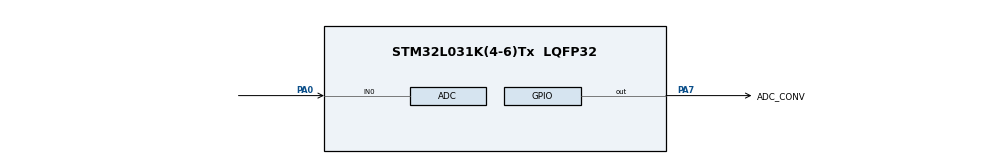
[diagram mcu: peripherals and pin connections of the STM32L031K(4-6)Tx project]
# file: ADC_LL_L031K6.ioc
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ADC.ClockPrescaler=ADC_CLOCK_SYNC_PCLK_DIV4
ADC.LowPowerFrequencyMode=ENABLE
ADC.OversamplingMode=ENABLE
ADC.Ratio=ADC_OVERSAMPLING_RATIO_16
ADC.RightBitShift=ADC_RIGHTBITSHIFT_4
ADC.SamplingTime=ADC_SAMPLETIME_160CYCLES_5
Mcu.Family=STM32L0
Mcu.Name=STM32L031K(4-6)Tx
Mcu.Package=LQFP32
PA0-CK_IN.Mode=IN0
PA0-CK_IN.Signal=ADC_IN0
PA13.GPIO_Label=TMS
PA13.Mode=Serial_Wire
PA13.Signal=SYS_SWDIO
PA14.GPIO_Label=TCK
PA14.Mode=Serial_Wire
PA14.Signal=SYS_SWCLK
PA7.GPIO_Label=ADC_CONV
PA7.GPIO_Speed=GPIO_SPEED_FREQ_VERY_HIGH
PA7.Signal=GPIO_Output
PC14-OSC32_IN.Mode=LSE-External-Oscillator
PC14-OSC32_IN.Signal=RCC_OSC32_IN
PC15-OSC32_OUT.Mode=LSE-External-Oscillator
PC15-OSC32_OUT.Signal=RCC_OSC32_OUT
ProjectManager.HeapSize=0x200
ProjectManager.StackSize=0x400
ProjectManager.TargetToolchain=STM32CubeIDE
RCC.AHBFreq_Value=32000000
RCC.APB1Freq_Value=32000000
RCC.APB1TimFreq_Value=32000000
RCC.APB2Freq_Value=32000000
RCC.APB2TimFreq_Value=32000000
RCC.HCLKFreq_Value=32000000
RCC.HSE_VALUE=8000000
RCC.HSI16_VALUE=16000000
RCC.HSI48_VALUE=48000000
RCC.HSI_VALUE=16000000
RCC.MSI_VALUE=2097000
RCC.PLLMUL=RCC_PLLMUL_4
RCC.SYSCLKFreq_VALUE=32000000
RCC.SYSCLKSource=RCC_SYSCLKSOURCE_PLLCLK
RCC.VCOOutputFreq_Value=64000000
VP_ADC_Vref_Input.Mode=IN-Vrefint
board=NUCLEO-L031K6

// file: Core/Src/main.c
/* USER CODE BEGIN Header */
/**
  ******************************************************************************
  * @file           : main.c
  * @brief          : Main program body
  ******************************************************************************
  * @attention
  *
  * Copyright (c) 2024 STMicroelectronics.
  * All rights reserved.
  *
  * This software is licensed under terms that can be found in the LICENSE file
  * in the root directory of this software component.
  * If no LICENSE file comes with this software, it is provided AS-IS.
  *
  ******************************************************************************
  */
/* USER CODE END Header */
#include "main.h"

/* USER CODE BEGIN PD */
#define VREFINT_CAL_ADDR                0x1FF80078  /* datasheet p. 19 */
#define VREFINT_CAL ((uint16_t*) VREFINT_CAL_ADDR)
#define VDDA_CHARAC						3.0
/* USER CODE END PD */

/* USER CODE BEGIN PV */
uint16_t adc_res1, adc_res2;
float adc_res1_V, adc_res2_V;
/* USER CODE END PV */

void SystemClock_Config(void);
static void MX_GPIO_Init(void);
static void MX_ADC_Init(void);

int main(void)
{

  /* MCU Configuration--------------------------------------------------------*/

  /* Reset of all peripherals, Initializes the Flash interface and the Systick. */
  LL_APB2_GRP1_EnableClock(LL_APB2_GRP1_PERIPH_SYSCFG);
  LL_APB1_GRP1_EnableClock(LL_APB1_GRP1_PERIPH_PWR);

  /* Configure the system clock */
  SystemClock_Config();

  /* Initialize all configured peripherals */
  MX_GPIO_Init();
  MX_ADC_Init();
  /* USER CODE BEGIN 2 */

  LL_ADC_StartCalibration(ADC1);
  while (LL_ADC_IsCalibrationOnGoing(ADC1));  // Wait until calibration is complete

  LL_ADC_Enable(ADC1);
  while (!LL_ADC_IsEnabled(ADC1)); // Wait until ADC is ready

  /* USER CODE END 2 */

  /* Infinite loop */
  /* USER CODE BEGIN WHILE */
  while (1)
  {
	  LL_GPIO_SetOutputPin(ADC_CONV_GPIO_Port, ADC_CONV_Pin);
	// Start ADC conversion
	LL_ADC_REG_StartConversion(ADC1);

	// Poll for conversion completion
	while (!LL_ADC_IsActiveFlag_EOC(ADC1));  // Wait for conversion to complete
	adc_res1 = LL_ADC_REG_ReadConversionData12(ADC1);

	 LL_GPIO_ResetOutputPin(ADC_CONV_GPIO_Port, ADC_CONV_Pin);
	 LL_ADC_ClearFlag_EOC(ADC1);

	// Start another ADC conversion
	 LL_GPIO_SetOutputPin(ADC_CONV_GPIO_Port, ADC_CONV_Pin);
	LL_ADC_REG_StartConversion(ADC1);

	// Poll for conversion completion
	while (!LL_ADC_IsActiveFlag_EOC(ADC1));  // Wait for conversion to complete
	adc_res2 = LL_ADC_REG_ReadConversionData12(ADC1);
	LL_GPIO_ResetOutputPin(ADC_CONV_GPIO_Port, ADC_CONV_Pin);

	// Clear EOC (End of Conversion) flag
	LL_ADC_ClearFlag_EOC(ADC1);

	// Calculate voltage values based on ADC readings
	adc_res2_V = VDDA_CHARAC * (*VREFINT_CAL) / adc_res2;
	adc_res1_V = (adc_res2_V / 4095.0) * adc_res1;

	// Add delay
	LL_mDelay(500);
    /* USER CODE END WHILE */

  }
}

void SystemClock_Config(void)
{
  LL_FLASH_SetLatency(LL_FLASH_LATENCY_1);
  while(LL_FLASH_GetLatency()!= LL_FLASH_LATENCY_1)
  {
  }
  LL_PWR_SetRegulVoltageScaling(LL_PWR_REGU_VOLTAGE_SCALE1);
  while (LL_PWR_IsActiveFlag_VOS() != 0)
  {
  }
  LL_RCC_HSI_Enable();

   /* Wait till HSI is ready */
  while(LL_RCC_HSI_IsReady() != 1)
  {

  }
  LL_RCC_HSI_SetCalibTrimming(16);
  LL_RCC_PLL_ConfigDomain_SYS(LL_RCC_PLLSOURCE_HSI, LL_RCC_PLL_MUL_4, LL_RCC_PLL_DIV_2);
  LL_RCC_PLL_Enable();

   /* Wait till PLL is ready */
  while(LL_RCC_PLL_IsReady() != 1)
  {

  }
  LL_RCC_SetAHBPrescaler(LL_RCC_SYSCLK_DIV_1);
  LL_RCC_SetAPB1Prescaler(LL_RCC_APB1_DIV_1);
  LL_RCC_SetAPB2Prescaler(LL_RCC_APB2_DIV_1);
  LL_RCC_SetSysClkSource(LL_RCC_SYS_CLKSOURCE_PLL);

   /* Wait till System clock is ready */
  while(LL_RCC_GetSysClkSource() != LL_RCC_SYS_CLKSOURCE_STATUS_PLL)
  {

  }

  LL_Init1msTick(32000000);

  LL_SetSystemCoreClock(32000000);
}

static void MX_ADC_Init(void)
{

  LL_ADC_REG_InitTypeDef ADC_REG_InitStruct = {0};
  LL_ADC_InitTypeDef ADC_InitStruct = {0};

  LL_GPIO_InitTypeDef GPIO_InitStruct = {0};

  /* Peripheral clock enable */
  LL_APB2_GRP1_EnableClock(LL_APB2_GRP1_PERIPH_ADC1);

  LL_IOP_GRP1_EnableClock(LL_IOP_GRP1_PERIPH_GPIOA);
  /**ADC GPIO Configuration
  PA0-CK_IN   ------> ADC_IN0
  */
  GPIO_InitStruct.Pin = LL_GPIO_PIN_0;
  GPIO_InitStruct.Mode = LL_GPIO_MODE_ANALOG;
  GPIO_InitStruct.Pull = LL_GPIO_PULL_NO;
  LL_GPIO_Init(GPIOA, &GPIO_InitStruct);

  /** Configure Regular Channel
  */
  LL_ADC_REG_SetSequencerChAdd(ADC1, LL_ADC_CHANNEL_0);

  /** Configure Regular Channel
  */
  LL_ADC_REG_SetSequencerChAdd(ADC1, LL_ADC_CHANNEL_VREFINT);
  LL_ADC_SetCommonPathInternalCh(__LL_ADC_COMMON_INSTANCE(ADC1), LL_ADC_PATH_INTERNAL_VREFINT);

  /** Common config
  */
  ADC_REG_InitStruct.TriggerSource = LL_ADC_REG_TRIG_SOFTWARE;
  ADC_REG_InitStruct.SequencerDiscont = LL_ADC_REG_SEQ_DISCONT_DISABLE;
  ADC_REG_InitStruct.ContinuousMode = LL_ADC_REG_CONV_SINGLE;
  ADC_REG_InitStruct.DMATransfer = LL_ADC_REG_DMA_TRANSFER_NONE;
  ADC_REG_InitStruct.Overrun = LL_ADC_REG_OVR_DATA_PRESERVED;
  LL_ADC_REG_Init(ADC1, &ADC_REG_InitStruct);
  LL_ADC_SetSamplingTimeCommonChannels(ADC1, LL_ADC_SAMPLINGTIME_160CYCLES_5);
  LL_ADC_SetOverSamplingScope(ADC1, LL_ADC_OVS_GRP_REGULAR_CONTINUED);
  LL_ADC_ConfigOverSamplingRatioShift(ADC1, LL_ADC_OVS_RATIO_16, LL_ADC_OVS_SHIFT_RIGHT_4);
  LL_ADC_SetOverSamplingDiscont(ADC1, LL_ADC_OVS_REG_CONT);
  LL_ADC_REG_SetSequencerScanDirection(ADC1, LL_ADC_REG_SEQ_SCAN_DIR_FORWARD);
  LL_ADC_SetCommonFrequencyMode(__LL_ADC_COMMON_INSTANCE(ADC1), LL_ADC_CLOCK_FREQ_MODE_LOW);
  LL_ADC_DisableIT_EOC(ADC1);
  LL_ADC_DisableIT_EOS(ADC1);
  ADC_InitStruct.Clock = LL_ADC_CLOCK_SYNC_PCLK_DIV4;
  ADC_InitStruct.Resolution = LL_ADC_RESOLUTION_12B;
  ADC_InitStruct.DataAlignment = LL_ADC_DATA_ALIGN_RIGHT;
  ADC_InitStruct.LowPowerMode = LL_ADC_LP_MODE_NONE;
  LL_ADC_Init(ADC1, &ADC_InitStruct);

  /* Enable ADC internal voltage regulator */
  LL_ADC_EnableInternalRegulator(ADC1);
  /* Delay for ADC internal voltage regulator stabilization. */
  /* Compute number of CPU cycles to wait for, from delay in us. */
  /* Note: Variable divided by 2 to compensate partially */
  /* CPU processing cycles (depends on compilation optimization). */
  /* Note: If system core clock frequency is below 200kHz, wait time */
  /* is only a few CPU processing cycles. */
  uint32_t wait_loop_index;
  wait_loop_index = ((LL_ADC_DELAY_INTERNAL_REGUL_STAB_US * (SystemCoreClock / (100000 * 2))) / 10);
  while(wait_loop_index != 0)
  {
    wait_loop_index--;
  }

}

static void MX_GPIO_Init(void)
{
  LL_GPIO_InitTypeDef GPIO_InitStruct = {0};

  /* GPIO Ports Clock Enable */
  LL_IOP_GRP1_EnableClock(LL_IOP_GRP1_PERIPH_GPIOC);
  LL_IOP_GRP1_EnableClock(LL_IOP_GRP1_PERIPH_GPIOA);
  LL_IOP_GRP1_EnableClock(LL_IOP_GRP1_PERIPH_GPIOB);

  /**/
  LL_GPIO_ResetOutputPin(ADC_CONV_GPIO_Port, ADC_CONV_Pin);

  /**/
  GPIO_InitStruct.Pin = LL_GPIO_PIN_1;
  GPIO_InitStruct.Mode = LL_GPIO_MODE_ANALOG;
  GPIO_InitStruct.Pull = LL_GPIO_PULL_NO;
  LL_GPIO_Init(GPIOA, &GPIO_InitStruct);

  /**/
  GPIO_InitStruct.Pin = LL_GPIO_PIN_2;
  GPIO_InitStruct.Mode = LL_GPIO_MODE_ANALOG;
  GPIO_InitStruct.Pull = LL_GPIO_PULL_NO;
  LL_GPIO_Init(GPIOA, &GPIO_InitStruct);

  /**/
  GPIO_InitStruct.Pin = LL_GPIO_PIN_3;
  GPIO_InitStruct.Mode = LL_GPIO_MODE_ANALOG;
  GPIO_InitStruct.Pull = LL_GPIO_PULL_NO;
  LL_GPIO_Init(GPIOA, &GPIO_InitStruct);

  /**/
  GPIO_InitStruct.Pin = LL_GPIO_PIN_4;
  GPIO_InitStruct.Mode = LL_GPIO_MODE_ANALOG;
  GPIO_InitStruct.Pull = LL_GPIO_PULL_NO;
  LL_GPIO_Init(GPIOA, &GPIO_InitStruct);

  /**/
  GPIO_InitStruct.Pin = LL_GPIO_PIN_5;
  GPIO_InitStruct.Mode = LL_GPIO_MODE_ANALOG;
  GPIO_InitStruct.Pull = LL_GPIO_PULL_NO;
  LL_GPIO_Init(GPIOA, &GPIO_InitStruct);

  /**/
  GPIO_InitStruct.Pin = LL_GPIO_PIN_6;
  GPIO_InitStruct.Mode = LL_GPIO_MODE_ANALOG;
  GPIO_InitStruct.Pull = LL_GPIO_PULL_NO;
  LL_GPIO_Init(GPIOA, &GPIO_InitStruct);

  /**/
  GPIO_InitStruct.Pin = ADC_CONV_Pin;
  GPIO_InitStruct.Mode = LL_GPIO_MODE_OUTPUT;
  GPIO_InitStruct.Speed = LL_GPIO_SPEED_FREQ_VERY_HIGH;
  GPIO_InitStruct.OutputType = LL_GPIO_OUTPUT_PUSHPULL;
  GPIO_InitStruct.Pull = LL_GPIO_PULL_NO;
  LL_GPIO_Init(ADC_CONV_GPIO_Port, &GPIO_InitStruct);

  /**/
  GPIO_InitStruct.Pin = LL_GPIO_PIN_0;
  GPIO_InitStruct.Mode = LL_GPIO_MODE_ANALOG;
  GPIO_InitStruct.Pull = LL_GPIO_PULL_NO;
  LL_GPIO_Init(GPIOB, &GPIO_InitStruct);

  /**/
  GPIO_InitStruct.Pin = LL_GPIO_PIN_1;
  GPIO_InitStruct.Mode = LL_GPIO_MODE_ANALOG;
  GPIO_InitStruct.Pull = LL_GPIO_PULL_NO;
  LL_GPIO_Init(GPIOB, &GPIO_InitStruct);

  /**/
  GPIO_InitStruct.Pin = LL_GPIO_PIN_8;
  GPIO_InitStruct.Mode = LL_GPIO_MODE_ANALOG;
  GPIO_InitStruct.Pull = LL_GPIO_PULL_NO;
  LL_GPIO_Init(GPIOA, &GPIO_InitStruct);

  /**/
  GPIO_InitStruct.Pin = LL_GPIO_PIN_9;
  GPIO_InitStruct.Mode = LL_GPIO_MODE_ANALOG;
  GPIO_InitStruct.Pull = LL_GPIO_PULL_NO;
  LL_GPIO_Init(GPIOA, &GPIO_InitStruct);

  /**/
  GPIO_InitStruct.Pin = LL_GPIO_PIN_10;
  GPIO_InitStruct.Mode = LL_GPIO_MODE_ANALOG;
  GPIO_InitStruct.Pull = LL_GPIO_PULL_NO;
  LL_GPIO_Init(GPIOA, &GPIO_InitStruct);

  /**/
  GPIO_InitStruct.Pin = LL_GPIO_PIN_11;
  GPIO_InitStruct.Mode = LL_GPIO_MODE_ANALOG;
  GPIO_InitStruct.Pull = LL_GPIO_PULL_NO;
  LL_GPIO_Init(GPIOA, &GPIO_InitStruct);

  /**/
  GPIO_InitStruct.Pin = LL_GPIO_PIN_12;
  GPIO_InitStruct.Mode = LL_GPIO_MODE_ANALOG;
  GPIO_InitStruct.Pull = LL_GPIO_PULL_NO;
  LL_GPIO_Init(GPIOA, &GPIO_InitStruct);

  /**/
  GPIO_InitStruct.Pin = LL_GPIO_PIN_15;
  GPIO_InitStruct.Mode = LL_GPIO_MODE_ANALOG;
  GPIO_InitStruct.Pull = LL_GPIO_PULL_NO;
  LL_GPIO_Init(GPIOA, &GPIO_InitStruct);

  /**/
  GPIO_InitStruct.Pin = LL_GPIO_PIN_3;
  GPIO_InitStruct.Mode = LL_GPIO_MODE_ANALOG;
  GPIO_InitStruct.Pull = LL_GPIO_PULL_NO;
  LL_GPIO_Init(GPIOB, &GPIO_InitStruct);

  /**/
  GPIO_InitStruct.Pin = LL_GPIO_PIN_4;
  GPIO_InitStruct.Mode = LL_GPIO_MODE_ANALOG;
  GPIO_InitStruct.Pull = LL_GPIO_PULL_NO;
  LL_GPIO_Init(GPIOB, &GPIO_InitStruct);

  /**/
  GPIO_InitStruct.Pin = LL_GPIO_PIN_5;
  GPIO_InitStruct.Mode = LL_GPIO_MODE_ANALOG;
  GPIO_InitStruct.Pull = LL_GPIO_PULL_NO;
  LL_GPIO_Init(GPIOB, &GPIO_InitStruct);

  /**/
  GPIO_InitStruct.Pin = LL_GPIO_PIN_6;
  GPIO_InitStruct.Mode = LL_GPIO_MODE_ANALOG;
  GPIO_InitStruct.Pull = LL_GPIO_PULL_NO;
  LL_GPIO_Init(GPIOB, &GPIO_InitStruct);

  /**/
  GPIO_InitStruct.Pin = LL_GPIO_PIN_7;
  GPIO_InitStruct.Mode = LL_GPIO_MODE_ANALOG;
  GPIO_InitStruct.Pull = LL_GPIO_PULL_NO;
  LL_GPIO_Init(GPIOB, &GPIO_InitStruct);

}

void Error_Handler(void)
{
  __disable_irq();
  while (1)
  {
  }
}
